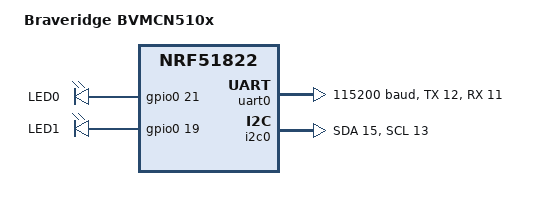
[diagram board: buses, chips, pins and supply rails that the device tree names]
/*
 * Copyright (c) 2019 hiro99ma
 *
 * SPDX-License-Identifier: Apache-2.0
 */

/dts-v1/;
#include <nordic/nrf51822_qfaa.dtsi>

/ {
	model = "Braveridge BVMCN510x";
	compatible = "braveridge,bvmcn51", "nordic,nrf51822-qfaa",
		     "nordic,nrf51822";

	chosen {
		zephyr,console = &uart0;
		zephyr,shell-uart = &uart0;
		zephyr,bt-mon-uart = &uart0;
		zephyr,bt-c2h-uart = &uart0;
		zephyr,sram = &sram0;
		zephyr,flash = &flash0;
	};

	aliases {
		led0 = &led0;
		led1 = &led1;
	};

	leds {
		compatible = "gpio-leds";
		led0: led_0 {
			gpios = <&gpio0 21 0>;
			label = "LED0";
		};
                led1: led_1 {
                        gpios = <&gpio0 19 0>;
                        label = "LED1";
                };
	};
};

&gpiote {
	status = "okay";
};

&gpio0 {
	status = "okay";
};

&uart0 {
	current-speed = <115200>;
	status = "okay";
	tx-pin = <12>;
	rx-pin = <11>;
};

&i2c0 {
	status = "okay";
	sda-pin = <15>;
	scl-pin = <13>;
};

